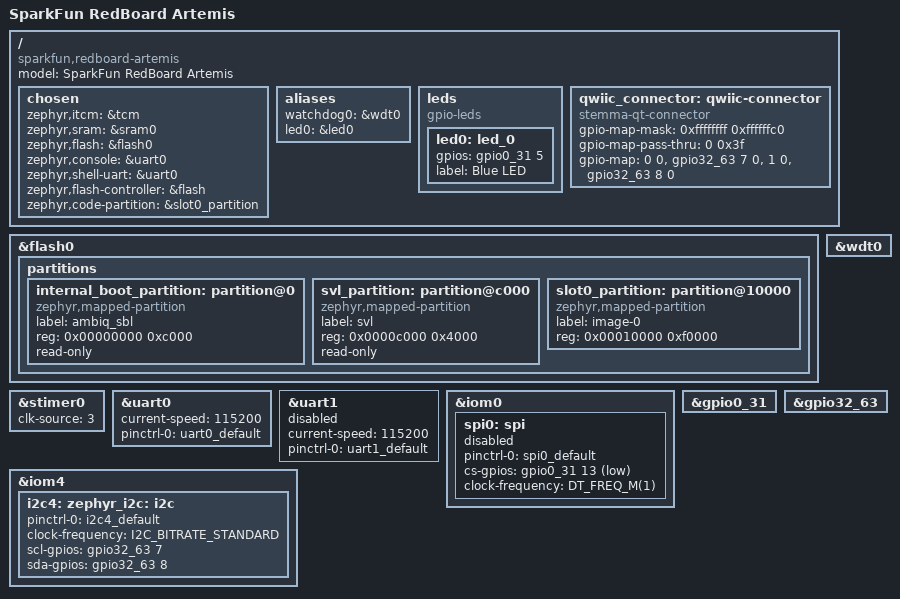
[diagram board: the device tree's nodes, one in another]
/*
 * SPDX-FileCopyrightText: Copyright The Zephyr Project Contributors
 *
 * SPDX-License-Identifier: Apache-2.0
 */

/dts-v1/;
#include <ambiq/ambiq_apollo3_blue.dtsi>

#include "sparkfun_redboard_artemis-pinctrl.dtsi"

/ {
	model = "SparkFun RedBoard Artemis";
	compatible = "sparkfun,redboard-artemis";

	chosen {
		zephyr,itcm = &tcm;
		zephyr,sram = &sram0;
		zephyr,flash = &flash0;
		zephyr,console = &uart0;
		zephyr,shell-uart = &uart0;
		zephyr,flash-controller = &flash;
		zephyr,code-partition = &slot0_partition;
	};

	aliases {
		watchdog0 = &wdt0;
		led0 = &led0;
	};

	leds {
		compatible = "gpio-leds";

		led0: led_0 {
			gpios = <&gpio0_31 5 GPIO_ACTIVE_HIGH>;
			label = "Blue LED";
		};
	};

	qwiic_connector: qwiic-connector {
		compatible = "stemma-qt-connector";
		#gpio-cells = <2>;
		gpio-map-mask = <0xffffffff 0xffffffc0>;
		gpio-map-pass-thru = <0 0x3f>;
		gpio-map = <0 0 &gpio32_63 7 0>,	/* SCL */
			   <1 0 &gpio32_63 8 0>;	/* SDA */
	};
};

&flash0 {
	partitions {
		ranges;
		#address-cells = <1>;
		#size-cells = <1>;

		internal_boot_partition: partition@0 {
			compatible = "zephyr,mapped-partition";
			label = "ambiq_sbl";
			reg = <0x00000000 0xc000>;
			read-only;
		};

		svl_partition: partition@c000 {
			compatible = "zephyr,mapped-partition";
			label = "svl";
			reg = <0x0000c000 0x4000>;
			read-only;
		};

		slot0_partition: partition@10000 {
			compatible = "zephyr,mapped-partition";
			label = "image-0";
			reg = <0x00010000 0xf0000>;
		};
	};
};

&stimer0 {
	clk-source = <3>;
};

&uart0 {
	current-speed = <115200>;
	pinctrl-0 = <&uart0_default>;
	pinctrl-names = "default";
	status = "okay";
};

&uart1 {
	current-speed = <115200>;
	pinctrl-0 = <&uart1_default>;
	pinctrl-names = "default";
	status = "disabled";
};

&iom0 {
	spi0: spi {
		pinctrl-0 = <&spi0_default>;
		pinctrl-names = "default";
		cs-gpios = <&gpio0_31 13 GPIO_ACTIVE_LOW>;
		clock-frequency = <DT_FREQ_M(1)>;
		status = "disabled";
	};
};

&iom4 {
	i2c4: i2c {
		pinctrl-0 = <&i2c4_default>;
		pinctrl-names = "default";
		clock-frequency = <I2C_BITRATE_STANDARD>;
		scl-gpios = <&gpio32_63 7 (GPIO_OPEN_DRAIN | GPIO_PULL_UP)>;
		sda-gpios = <&gpio32_63 8 (GPIO_OPEN_DRAIN | GPIO_PULL_UP)>;
		status = "okay";
	};
};

&wdt0 {
	status = "okay";
};

&gpio0_31 {
	status = "okay";
};

&gpio32_63 {
	status = "okay";
};

zephyr_i2c: &i2c4 {};

#include "arduino_r3_connector.dtsi"
